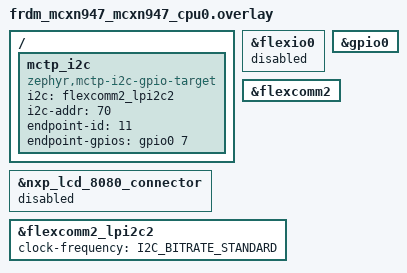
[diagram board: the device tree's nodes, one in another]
#include <zephyr/dt-bindings/gpio/gpio.h>

/* Sets up I2C and a GPIO on JP8 to use as our i2c bus for MCTP.
 * SDA: J2.18
 * SCL: J2.20
 * GPIO: J8.8
 * GND: J8.2
 */

&nxp_lcd_8080_connector {
	status = "disabled";
};

&flexio0 {
	status = "disabled";
};

&gpio0 {
	status = "okay";
};

&flexcomm2 {
	status = "okay";
};

&flexcomm2_lpi2c2 {
	status = "okay";
	clock-frequency = <I2C_BITRATE_STANDARD>;
};

/ {
	mctp_i2c: mctp_i2c {
		compatible = "zephyr,mctp-i2c-gpio-target";
		i2c = <&flexcomm2_lpi2c2>;
		i2c-addr = <70>;
		endpoint-id = <11>;
		endpoint-gpios = <&gpio0 7 GPIO_ACTIVE_HIGH>;
	};
};
